# LargeDummyDevice register map
File version: 1.0
Registers are 32-bit, read-write, no defined reset value unless marked. A register's access mark holds for its fields unless they carry their own. Offsets are from the block's base; [hi:lo] are bit positions.

## PERIPHERAL_30
Base 0x4001D000
0x04 REG_1 — Register 1
  [31] FIELD_14, [33:31] FIELD_17, [34:30] FIELD_26, [31:29] FIELD_11, [33:29] FIELD_15, [31:29] FIELD_24, [33:29] FIELD_30, [26] FIELD_5, [28:25] FIELD_21, [26:24] FIELD_10, [28:24] FIELD_18, [26:22] FIELD_9, [20:19] FIELD_19, [15] FIELD_22, [14:12] FIELD_1, [13:11] FIELD_25, [13:11] FIELD_27, [11:10] FIELD_3, [10:9] FIELD_8, [8] FIELD_6, [7:5] FIELD_20, [9:5] FIELD_28, [5:4] FIELD_16, [4] FIELD_29, [5:3] FIELD_12, [3:2] FIELD_2, [6:2] FIELD_7, [2:0] FIELD_4, [3:0] FIELD_13, [2:0] FIELD_23
0x08 REG_2 — Register 2
  [32:30] FIELD_3, [30:26] FIELD_2, [28:25] FIELD_1, [17:13] FIELD_5, [15:13] FIELD_6, [15:12] FIELD_4, [10:7] FIELD_7, [9:6] FIELD_8
0x0C REG_3 — Register 3
  [28] FIELD_8, [28:26] FIELD_2, [29:26] FIELD_13, [24] FIELD_1, [20:19] FIELD_5, [20:16] FIELD_12, [13:10] FIELD_4, [8:7] FIELD_7, [4] FIELD_10, [6:3] FIELD_9, [7:3] FIELD_11, [5:2] FIELD_6, [4:1] FIELD_3
0x10 REG_4 — Register 4
  [30:27] FIELD_9, [24] FIELD_5, [25:24] FIELD_7, [24] FIELD_8, [23] FIELD_2, [14:10] FIELD_1, [11:10] FIELD_6, [10:6] FIELD_3, [7:6] FIELD_4, [6] FIELD_10
0x14 REG_5 — Register 5
  [33:31] FIELD_22, [29] FIELD_8, [32:28] FIELD_4, [28:27] FIELD_10, [27:24] FIELD_6, [23:22] FIELD_14, [20] FIELD_2, [23:20] FIELD_3, [20] FIELD_21, [22:18] FIELD_17, [18:16] FIELD_15, [15] FIELD_1, [16:15] FIELD_19, [14] FIELD_20, [10] FIELD_7, [13:9] FIELD_12, [11:9] FIELD_16, [7:6] FIELD_5, [7:6] FIELD_18, [5:4] FIELD_9, [5:2] FIELD_11, [1:0] FIELD_13
0x18 REG_6 — Register 6
  [14] FIELD_1
0x1C REG_7 — Register 7
  [33:29] FIELD_23, [28:27] FIELD_10, [27] FIELD_13, [25] FIELD_18, [27:24] FIELD_25, [23] FIELD_7, [26:22] FIELD_15, [25:22] FIELD_26, [20:18] FIELD_3, [19:16] FIELD_14, [20:16] FIELD_17, [16:15] FIELD_4, [17:15] FIELD_9, [17:14] FIELD_12, [18:14] FIELD_21, [12:11] FIELD_24, [13:9] FIELD_5, [10:9] FIELD_16, [9:8] FIELD_2, [7] FIELD_8, [10:6] FIELD_19, [7:3] FIELD_6, [5:1] FIELD_11, [4:1] FIELD_20, [3:1] FIELD_22, [3:0] FIELD_1
0x20 REG_8 — Register 8
  [34:30] FIELD_9, [32:29] FIELD_4, [29:28] FIELD_15, [19:18] FIELD_13, [21:17] FIELD_14, [15:12] FIELD_2, [15:11] FIELD_8, [11:8] FIELD_1, [10:8] FIELD_10, [9:6] FIELD_12, [9:5] FIELD_3, [5:4] FIELD_7, [5:2] FIELD_5, [6:2] FIELD_6, [3:1] FIELD_11
0x24 REG_9 — Register 9
  [35:31] FIELD_4, [30:28] FIELD_10, [24:22] FIELD_7, [21:17] FIELD_8, [19:17] FIELD_9, [14] FIELD_1, [9] FIELD_2, [8:4] FIELD_3, [5:3] FIELD_6, [2] FIELD_5
0x28 REG_10 — Register 10
  [34:31] FIELD_2, [34:31] FIELD_19, [33:29] FIELD_8, [30:28] FIELD_4, [32:28] FIELD_7, [31:28] FIELD_9, [32:28] FIELD_20, [29:26] FIELD_18, [26:24] FIELD_15, [24:23] FIELD_17, [18] FIELD_5, [20:18] FIELD_12, [17:16] FIELD_10, [17:16] FIELD_11, [19:16] FIELD_21, [13:11] FIELD_13, [14:11] FIELD_22, [9:7] FIELD_6, [6] FIELD_3, [6:3] FIELD_23, [5:2] FIELD_1, [3:2] FIELD_16, [3:0] FIELD_14
0x2C REG_11 — Register 11
  [31] FIELD_24, [34:30] FIELD_10, [30] FIELD_19, [29] FIELD_13, [32:29] FIELD_29, [27:25] FIELD_21, [24:23] FIELD_11, [22:21] FIELD_30, [21:20] FIELD_1, [22:19] FIELD_16, [17] FIELD_6, [17] FIELD_25, [19:15] FIELD_5, [18:15] FIELD_17, [13] FIELD_31, [12] FIELD_22, [16:12] FIELD_23, [12:10] FIELD_28, [10:8] FIELD_12, [10:7] FIELD_18, [8:7] FIELD_20, [7:4] FIELD_7, [3] FIELD_2, [4:3] FIELD_4, [5:3] FIELD_8, [2] FIELD_3, [4:1] FIELD_14, [4:1] FIELD_15, [3:1] FIELD_26, [0] FIELD_9, [2:0] FIELD_27
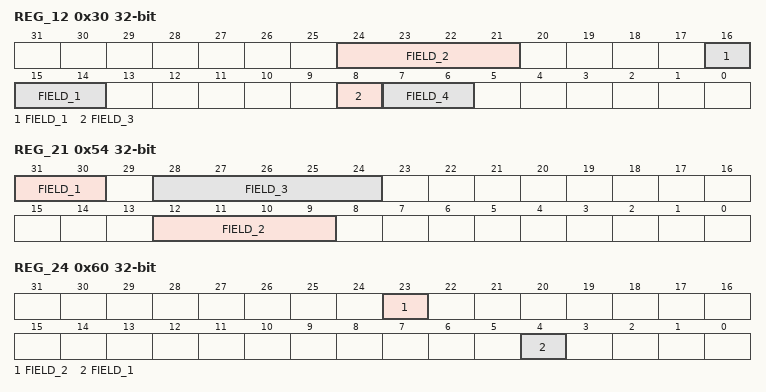
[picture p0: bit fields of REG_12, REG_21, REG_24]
0x30 REG_12 — Register 12
  [24:21] FIELD_2, [16:14] FIELD_1, [8] FIELD_3, [7:6] FIELD_4
0x34 REG_13 — Register 13
  [32:30] FIELD_5, [30:26] FIELD_1, [21:20] FIELD_2, [11:9] FIELD_4, [10:9] FIELD_6, [5:3] FIELD_3
0x38 REG_14 — Register 14
  [31] FIELD_13, [31:29] FIELD_9, [30:27] FIELD_8, [26] FIELD_11, [23:21] FIELD_2, [21] FIELD_7, [23:20] FIELD_14, [21:18] FIELD_12, [17:14] FIELD_1, [13:11] FIELD_4, [13:9] FIELD_5, [8:5] FIELD_3, [8:5] FIELD_10, [1:0] FIELD_6
0x3C REG_15 — Register 15
  [32:30] FIELD_2, [29:28] FIELD_5, [28:27] FIELD_10, [26] FIELD_9, [27:24] FIELD_12, [23:22] FIELD_7, [22:21] FIELD_8, [17:16] FIELD_6, [15:11] FIELD_1, [8:5] FIELD_4, [7:5] FIELD_13, [1] FIELD_3, [0] FIELD_11
0x40 REG_16 — Register 16
  [34:30] FIELD_4, [29:28] FIELD_2, [27:25] FIELD_6, [23] FIELD_3, [27:23] FIELD_7, [21:19] FIELD_14, [16] FIELD_9, [15] FIELD_10, [14:11] FIELD_1, [12:10] FIELD_12, [10:9] FIELD_5, [12:9] FIELD_13, [6] FIELD_8, [4] FIELD_11
0x44 REG_17 — Register 17
  [33:29] FIELD_2, [30:29] FIELD_3, [27:25] FIELD_4, [23] FIELD_6, [11:9] FIELD_5, [9:5] FIELD_1
0x48 REG_18 — Register 18
  [35:31] FIELD_22, [29] FIELD_2, [29] FIELD_16, [31:28] FIELD_3, [31:27] FIELD_7, [30:27] FIELD_13, [28:27] FIELD_25, [27:26] FIELD_8, [28:25] FIELD_5, [24] FIELD_28, [24:23] FIELD_18, [24:23] FIELD_27, [22:21] FIELD_11, [20:17] FIELD_1, [19:17] FIELD_23, [16] FIELD_19, [15] FIELD_4, [15:13] FIELD_14, [13:11] FIELD_6, [11] FIELD_21, [14:10] FIELD_24, [10:6] FIELD_9, [5] FIELD_12, [6:5] FIELD_15, [4] FIELD_20, [3] FIELD_10, [6:3] FIELD_29, [1] FIELD_26, [4:0] FIELD_17
0x4C REG_19 — Register 19
  [31] FIELD_1, [29:28] FIELD_3, [30:28] FIELD_7, [31:27] FIELD_13, [25:24] FIELD_8, [25:22] FIELD_11, [18:17] FIELD_10, [12] FIELD_5, [13:12] FIELD_9, [10] FIELD_6, [10:7] FIELD_12, [7:6] FIELD_2, [10:6] FIELD_15, [6:5] FIELD_4, [3:1] FIELD_16, [0] FIELD_14
0x50 REG_20 — Register 20
  [20:17] FIELD_1
0x54 REG_21 — Register 21
  [31:30] FIELD_1, [28:24] FIELD_3, [12:9] FIELD_2
0x58 REG_22 — Register 22
  [29:26] FIELD_6, [30:26] FIELD_8, [26:24] FIELD_5, [22] FIELD_3, [25:22] FIELD_10, [22:20] FIELD_1, [21:18] FIELD_2, [21:17] FIELD_12, [16] FIELD_9, [20:16] FIELD_17, [18:15] FIELD_11, [13] FIELD_18, [14:12] FIELD_16, [13:11] FIELD_19, [9] FIELD_7, [5] FIELD_4, [9:5] FIELD_20, [5:2] FIELD_14, [2] FIELD_15, [0] FIELD_13
0x5C REG_23 — Register 23
  [35:31] FIELD_4, [32:29] FIELD_25, [29:27] FIELD_27, [28:25] FIELD_8, [23] FIELD_6, [26:23] FIELD_15, [26:23] FIELD_18, [25:23] FIELD_22, [26:23] FIELD_23, [25:22] FIELD_1, [21:18] FIELD_28, [19:17] FIELD_9, [16] FIELD_17, [17:15] FIELD_14, [14] FIELD_10, [14] FIELD_12, [17:14] FIELD_13, [10:7] FIELD_20, [8:6] FIELD_26, [7:5] FIELD_16, [6:4] FIELD_2, [7:4] FIELD_3, [8:4] FIELD_24, [6:2] FIELD_5, [6:2] FIELD_7, [2:0] FIELD_11, [0] FIELD_19, [2:0] FIELD_21
0x60 REG_24 — Register 24
  [23] FIELD_2, [4] FIELD_1
0x64 REG_25 — Register 25
  [31] FIELD_10, [34:31] FIELD_13, [35:31] FIELD_21, [31:27] FIELD_11, [29:26] FIELD_4, [26:25] FIELD_14, [25] FIELD_22, [20] FIELD_18, [22:20] FIELD_19, [20:18] FIELD_9, [21:18] FIELD_12, [21:17] FIELD_1, [19:16] FIELD_8, [13] FIELD_16, [16:12] FIELD_7, [9] FIELD_5, [13:9] FIELD_6, [12:9] FIELD_20, [11:7] FIELD_3, [2] FIELD_2, [4:2] FIELD_17, [2:0] FIELD_15
0x68 REG_26 — Register 26
  [34:31] FIELD_17, [33:30] FIELD_7, [29:28] FIELD_3, [29:26] FIELD_6, [19] FIELD_11, [19] FIELD_14, [23:19] FIELD_16, [17] FIELD_12, [17:15] FIELD_18, [14:10] FIELD_4, [9:8] FIELD_10, [9:7] FIELD_9, [7:6] FIELD_8, [10:6] FIELD_13, [9:5] FIELD_19, [7:4] FIELD_2, [4] FIELD_5, [4] FIELD_15, [5:3] FIELD_1, [3:2] FIELD_20
0x6C REG_27 — Register 27
  [34:31] FIELD_10, [32:31] FIELD_11, [34:31] FIELD_21, [31:28] FIELD_3, [29:27] FIELD_15, [27:24] FIELD_13, [22] FIELD_5, [21:20] FIELD_6, [20] FIELD_9, [20:19] FIELD_2, [20:19] FIELD_14, [21:19] FIELD_18, [22:18] FIELD_19, [20:17] FIELD_17, [16:13] FIELD_7, [15:11] FIELD_22, [14:10] FIELD_8, [8:6] FIELD_1, [9:6] FIELD_16, [8:5] FIELD_12, [8:5] FIELD_20, [8:4] FIELD_4
0x70 REG_28 — Register 28
  [31] FIELD_7, [32:28] FIELD_4, [27] FIELD_5, [21] FIELD_9, [20] FIELD_8, [18:17] FIELD_2, [16:15] FIELD_3, [7:4] FIELD_1, [5:1] FIELD_6
0x74 REG_29 — Register 29
  [29] FIELD_5, [29:26] FIELD_4, [25:22] FIELD_6, [19:17] FIELD_2, [10:6] FIELD_3, [5:1] FIELD_1
0x78 REG_30 — Register 30
  [31:29] FIELD_1, [31:29] FIELD_4, [31:29] FIELD_7, [29:26] FIELD_10, [28:26] FIELD_17, [28:24] FIELD_15, [26:22] FIELD_16, [22:20] FIELD_3, [23:20] FIELD_18, [20:19] FIELD_9, [19:16] FIELD_5, [16:15] FIELD_2, [17:15] FIELD_6, [16:12] FIELD_11, [13:11] FIELD_12, [11:8] FIELD_13, [8:7] FIELD_8, [5:4] FIELD_14
0x7C REG_31 — Register 31
  [33:30] FIELD_16, [29:28] FIELD_11, [31:28] FIELD_14, [31:28] FIELD_18, [29:28] FIELD_20, [28:27] FIELD_6, [29:25] FIELD_2, [26:25] FIELD_10, [29:25] FIELD_13, [27:24] FIELD_9, [23:21] FIELD_17, [23:20] FIELD_5, [22:18] FIELD_15, [16] FIELD_12, [18:14] FIELD_4, [17:14] FIELD_8, [17:14] FIELD_19, [12] FIELD_3, [12] FIELD_7, [10:7] FIELD_1, [7] FIELD_21
0x80 REG_32 — Register 32
  [33:30] FIELD_9, [31:28] FIELD_2, [27:25] FIELD_12, [22] FIELD_16, [21:20] FIELD_8, [22:19] FIELD_7, [18] FIELD_19, [15] FIELD_13, [16:14] FIELD_5, [17:13] FIELD_17, [12] FIELD_4, [12:9] FIELD_1, [11:8] FIELD_14, [9:8] FIELD_18, [8:4] FIELD_6, [3] FIELD_3, [2] FIELD_10, [2] FIELD_11, [2] FIELD_20, [3:1] FIELD_15, [0] FIELD_21
0x84 REG_33 — Register 33
  [31] FIELD_16, [33:30] FIELD_4, [29:28] FIELD_6, [25:23] FIELD_10, [22:21] FIELD_9, [24:20] FIELD_1, [22:19] FIELD_13, [21:18] FIELD_8, [15:14] FIELD_3, [15:14] FIELD_15, [11:7] FIELD_5, [10:7] FIELD_7, [9:7] FIELD_14, [6:4] FIELD_2, [5:4] FIELD_11, [5:2] FIELD_12
0x88 REG_34 — Register 34
  [34:31] FIELD_17, [31:29] FIELD_11, [30:28] FIELD_21, [31:27] FIELD_5, [26:25] FIELD_8, [29:25] FIELD_9, [26:22] FIELD_4, [23:21] FIELD_7, [22:19] FIELD_1, [20:17] FIELD_18, [14] FIELD_14, [14:12] FIELD_15, [11] FIELD_10, [10] FIELD_6, [11:10] FIELD_20, [13:9] FIELD_12, [9] FIELD_13, [10:7] FIELD_2, [9:7] FIELD_16, [10:7] FIELD_19, [1] FIELD_3
0x8C REG_35 — Register 35
  [34:30] FIELD_13, [30:29] FIELD_7, [31:29] FIELD_9, [32:28] FIELD_5, [30:28] FIELD_11, [21] FIELD_2, [24:20] FIELD_1, [24:20] FIELD_12, [18] FIELD_10, [17:15] FIELD_4, [14] FIELD_17, [15:13] FIELD_6, [15:12] FIELD_14, [12:10] FIELD_3, [8:6] FIELD_16, [9:5] FIELD_8, [9:5] FIELD_15
0x90 REG_36 — Register 36
  [31:30] FIELD_20, [31:27] FIELD_13, [29:26] FIELD_5, [25:22] FIELD_3, [23:21] FIELD_21, [22:20] FIELD_4, [20] FIELD_11, [19] FIELD_23, [19:17] FIELD_1, [17] FIELD_19, [19:16] FIELD_18, [15] FIELD_15, [17:14] FIELD_2, [15:11] FIELD_12, [13:11] FIELD_14, [12:8] FIELD_16, [8:6] FIELD_7, [7:6] FIELD_17, [6] FIELD_22, [4:2] FIELD_10, [1] FIELD_9, [0] FIELD_6, [3:0] FIELD_8
0x94 REG_37 — Register 37
  [33:30] FIELD_10, [33:30] FIELD_20, [29] FIELD_3, [32:28] FIELD_5, [28] FIELD_15, [30:26] FIELD_8, [29:25] FIELD_9, [27:24] FIELD_22, [25:23] FIELD_6, [26:22] FIELD_2, [25:22] FIELD_25, [21:20] FIELD_14, [21:20] FIELD_16, [23:19] FIELD_21, [21:19] FIELD_24, [18] FIELD_1, [20:18] FIELD_13, [12:9] FIELD_27, [9:8] FIELD_12, [10:7] FIELD_18, [10:6] FIELD_4, [9:6] FIELD_17, [7:5] FIELD_19, [8:5] FIELD_26, [5:4] FIELD_7, [3] FIELD_23, [5:1] FIELD_11
0x98 REG_38 — Register 38
  [33:31] FIELD_5, [34:31] FIELD_6, [34:30] FIELD_7, [32:29] FIELD_4, [33:29] FIELD_14, [31:28] FIELD_8, [26:22] FIELD_9, [21:20] FIELD_1, [20] FIELD_16, [24:20] FIELD_23, [22:19] FIELD_10, [19:16] FIELD_13, [16:15] FIELD_19, [16:14] FIELD_20, [10] FIELD_3, [9] FIELD_2, [12:9] FIELD_22, [7:6] FIELD_18, [4] FIELD_12, [6:4] FIELD_21, [1] FIELD_15, [4:0] FIELD_11, [0] FIELD_17
0x9C REG_39 — Register 39
  [31:28] FIELD_19, [27] FIELD_3, [27] FIELD_20, [27:25] FIELD_23, [25:24] FIELD_17, [22] FIELD_13, [20] FIELD_5, [18] FIELD_4, [18:17] FIELD_7, [20:16] FIELD_11, [17:16] FIELD_22, [18:14] FIELD_10, [12:9] FIELD_2, [12:8] FIELD_12, [9:7] FIELD_8, [11:7] FIELD_14, [10:6] FIELD_21, [6:5] FIELD_6, [5] FIELD_15, [4:3] FIELD_24, [1] FIELD_1, [3:1] FIELD_16, [4:0] FIELD_9, [4:0] FIELD_18
0xA0 REG_40 — Register 40
  [33:29] FIELD_6, [27] FIELD_17, [29:27] FIELD_22, [27:24] FIELD_21, [23] FIELD_12, [27:23] FIELD_27, [26:22] FIELD_1, [26:22] FIELD_13, [22] FIELD_25, [22:21] FIELD_4, [24:20] FIELD_2, [21:18] FIELD_10, [21:18] FIELD_15, [22:18] FIELD_19, [15] FIELD_3, [15] FIELD_9, [15:13] FIELD_20, [16:12] FIELD_16, [16:12] FIELD_18, [13:10] FIELD_11, [12:10] FIELD_23, [10:8] FIELD_5, [9:8] FIELD_7, [9:7] FIELD_26, [7:6] FIELD_14, [3] FIELD_8, [4:1] FIELD_24
